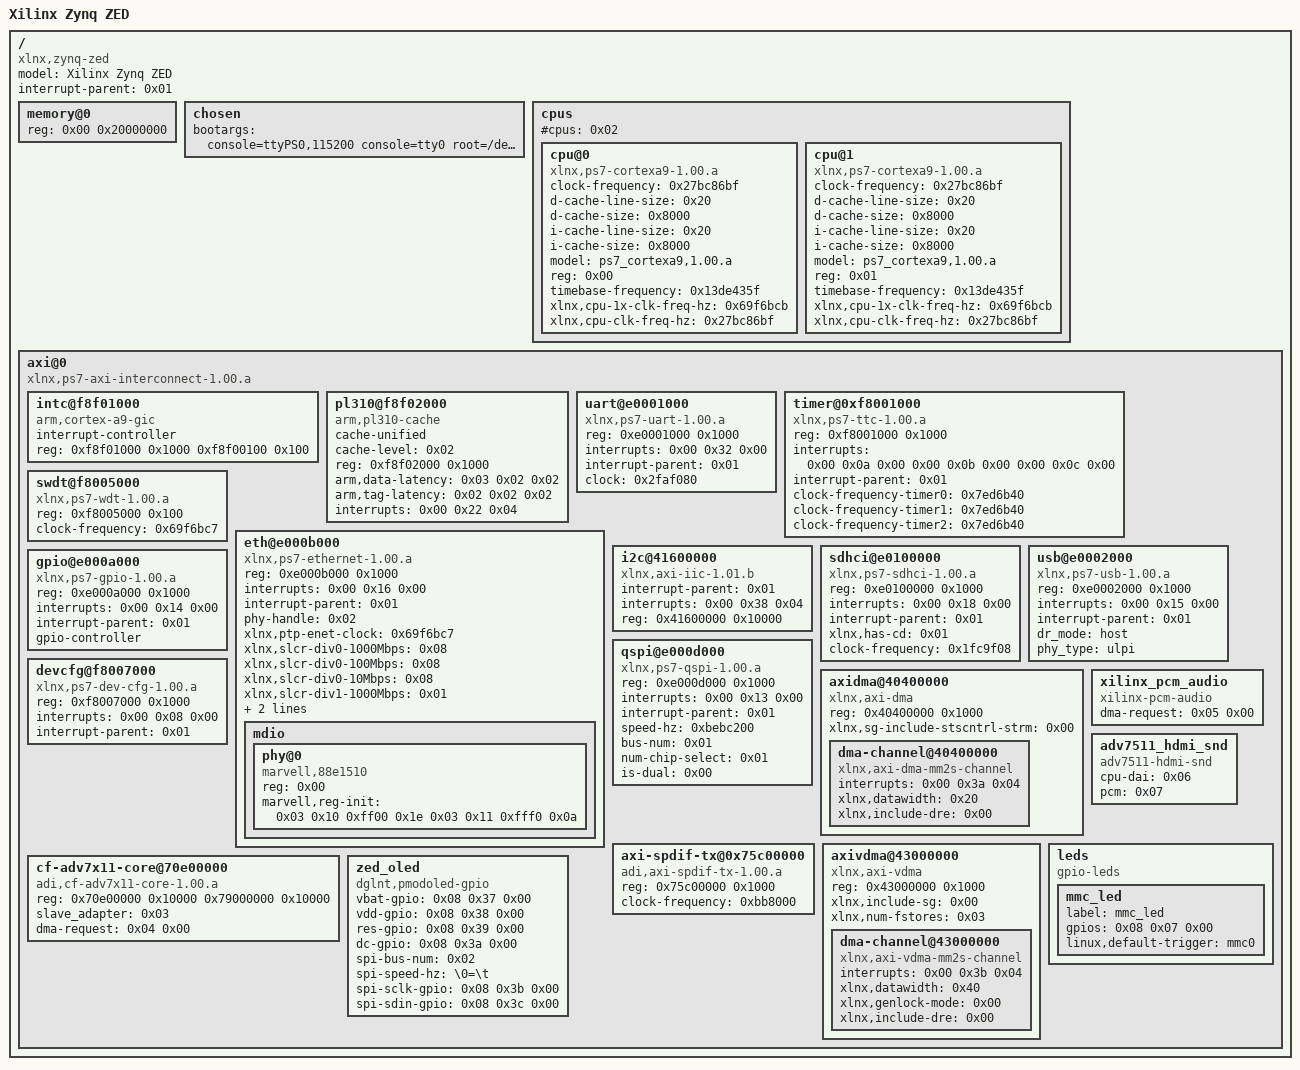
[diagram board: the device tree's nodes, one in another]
/dts-v1/;

/ {
	model = "Xilinx Zynq ZED";
	compatible = "xlnx,zynq-zed";
	#address-cells = <0x01>;
	#size-cells = <0x01>;
	interrupt-parent = <0x01>;

	memory@0 {
		device_type = "memory";
		reg = <0x00 0x20000000>;
	};

	chosen {
		bootargs = "console=ttyPS0,115200 console=tty0 root=/dev/ram rw initrd=0x800000,8M earlyprintk rootfstype=ext4 rootwait devtmpfs.mount=0";
		// linux,stdout-path = "/axi@0/uart@E0001000";
	};

	cpus {
		#address-cells = <0x01>;
		#cpus = <0x02>;
		#size-cells = <0x00>;

		cpu@0 {
			clock-frequency = <0x27bc86bf>;
			compatible = "xlnx,ps7-cortexa9-1.00.a";
			d-cache-line-size = <0x20>;
			d-cache-size = <0x8000>;
			device_type = "cpu";
			i-cache-line-size = <0x20>;
			i-cache-size = <0x8000>;
			model = "ps7_cortexa9,1.00.a";
			reg = <0x00>;
			timebase-frequency = <0x13de435f>;
			xlnx,cpu-1x-clk-freq-hz = <0x69f6bcb>;
			xlnx,cpu-clk-freq-hz = <0x27bc86bf>;
		};

		cpu@1 {
			clock-frequency = <0x27bc86bf>;
			compatible = "xlnx,ps7-cortexa9-1.00.a";
			d-cache-line-size = <0x20>;
			d-cache-size = <0x8000>;
			device_type = "cpu";
			i-cache-line-size = <0x20>;
			i-cache-size = <0x8000>;
			model = "ps7_cortexa9,1.00.a";
			reg = <0x01>;
			timebase-frequency = <0x13de435f>;
			xlnx,cpu-1x-clk-freq-hz = <0x69f6bcb>;
			xlnx,cpu-clk-freq-hz = <0x27bc86bf>;
		};
	};

	axi@0 {
		#address-cells = <0x01>;
		#size-cells = <0x01>;
		compatible = "xlnx,ps7-axi-interconnect-1.00.a\0simple-bus";
		ranges;

		intc@f8f01000 {
			interrupt-controller;
			compatible = "arm,cortex-a9-gic";
			#interrupt-cells = <0x03>;
			reg = <0xf8f01000 0x1000 0xf8f00100 0x100>;
			linux,phandle = <0x01>;
			phandle = <0x01>;
		};

		pl310@f8f02000 {
			compatible = "arm,pl310-cache";
			cache-unified;
			cache-level = <0x02>;
			reg = <0xf8f02000 0x1000>;
			arm,data-latency = <0x03 0x02 0x02>;
			arm,tag-latency = <0x02 0x02 0x02>;
			interrupts = <0x00 0x22 0x04>;
		};

		uart@e0001000 {
			compatible = "xlnx,ps7-uart-1.00.a";
			reg = <0xe0001000 0x1000>;
			interrupts = <0x00 0x32 0x00>;
			interrupt-parent = <0x01>;
			clock = <0x2faf080>;
		};

		timer@0xf8001000 {
			compatible = "xlnx,ps7-ttc-1.00.a";
			reg = <0xf8001000 0x1000>;
			interrupts = <0x00 0x0a 0x00 0x00 0x0b 0x00 0x00 0x0c 0x00>;
			interrupt-parent = <0x01>;
			clock-frequency-timer0 = <0x7ed6b40>;
			clock-frequency-timer1 = <0x7ed6b40>;
			clock-frequency-timer2 = <0x7ed6b40>;
		};

		swdt@f8005000 {
			device_type = "watchdog";
			compatible = "xlnx,ps7-wdt-1.00.a";
			reg = <0xf8005000 0x100>;
			clock-frequency = <0x69f6bc7>;
		};

		eth@e000b000 {
			compatible = "xlnx,ps7-ethernet-1.00.a";
			reg = <0xe000b000 0x1000>;
			interrupts = <0x00 0x16 0x00>;
			interrupt-parent = <0x01>;
			phy-handle = <0x02>;
			#address-cells = <0x01>;
			#size-cells = <0x00>;
			xlnx,ptp-enet-clock = <0x69f6bc7>;
			xlnx,slcr-div0-1000Mbps = <0x08>;
			xlnx,slcr-div0-100Mbps = <0x08>;
			xlnx,slcr-div0-10Mbps = <0x08>;
			xlnx,slcr-div1-1000Mbps = <0x01>;
			xlnx,slcr-div1-100Mbps = <0x05>;
			xlnx,slcr-div1-10Mbps = <0x32>;

			mdio {
				#address-cells = <0x01>;
				#size-cells = <0x00>;

				phy@0 {
					compatible = "marvell,88e1510";
					device_type = "ethernet-phy";
					reg = <0x00>;
					marvell,reg-init = <0x03 0x10 0xff00 0x1e 0x03 0x11 0xfff0 0x0a>;
					linux,phandle = <0x02>;
					phandle = <0x02>;
				};
			};
		};

		i2c@41600000 {
			compatible = "xlnx,axi-iic-1.01.b\0xlnx,xps-iic-2.00.a";
			interrupt-parent = <0x01>;
			interrupts = <0x00 0x38 0x04>;
			reg = <0x41600000 0x10000>;
			#size-cells = <0x00>;
			#address-cells = <0x01>;
			linux,phandle = <0x03>;
			phandle = <0x03>;
		};

		sdhci@e0100000 {
			compatible = "xlnx,ps7-sdhci-1.00.a";
			reg = <0xe0100000 0x1000>;
			interrupts = <0x00 0x18 0x00>;
			interrupt-parent = <0x01>;
			xlnx,has-cd = <0x01>;
			clock-frequency = <0x1fc9f08>;
		};

		usb@e0002000 {
			compatible = "xlnx,ps7-usb-1.00.a";
			reg = <0xe0002000 0x1000>;
			interrupts = <0x00 0x15 0x00>;
			interrupt-parent = <0x01>;
			dr_mode = "host";
			phy_type = "ulpi";
		};

		gpio@e000a000 {
			compatible = "xlnx,ps7-gpio-1.00.a";
			#gpio-cells = <0x02>;
			reg = <0xe000a000 0x1000>;
			interrupts = <0x00 0x14 0x00>;
			interrupt-parent = <0x01>;
			gpio-controller;
			linux,phandle = <0x08>;
			phandle = <0x08>;
		};

		qspi@e000d000 {
			compatible = "xlnx,ps7-qspi-1.00.a";
			reg = <0xe000d000 0x1000>;
			interrupts = <0x00 0x13 0x00>;
			interrupt-parent = <0x01>;
			speed-hz = <0xbebc200>;
			bus-num = <0x01>;
			num-chip-select = <0x01>;
			is-dual = <0x00>;
		};

		devcfg@f8007000 {
			compatible = "xlnx,ps7-dev-cfg-1.00.a";
			reg = <0xf8007000 0x1000>;
			interrupts = <0x00 0x08 0x00>;
			interrupt-parent = <0x01>;
		};

		axidma@40400000 {
			#address-cells = <0x01>;
			#size-cells = <0x01>;
			#dma-cells = <0x01>;
			compatible = "xlnx,axi-dma";
			reg = <0x40400000 0x1000>;
			xlnx,sg-include-stscntrl-strm = <0x00>;
			linux,phandle = <0x05>;
			phandle = <0x05>;

			dma-channel@40400000 {
				compatible = "xlnx,axi-dma-mm2s-channel";
				interrupts = <0x00 0x3a 0x04>;
				xlnx,datawidth = <0x20>;
				xlnx,include-dre = <0x00>;
			};
		};

		axi-spdif-tx@0x75c00000 {
			compatible = "adi,axi-spdif-tx-1.00.a";
			reg = <0x75c00000 0x1000>;
			clock-frequency = <0xbb8000>;
			linux,phandle = <0x06>;
			phandle = <0x06>;
		};

		axivdma@43000000 {
			#address-cells = <0x01>;
			#size-cells = <0x01>;
			#dma-cells = <0x01>;
			compatible = "xlnx,axi-vdma";
			reg = <0x43000000 0x1000>;
			xlnx,include-sg = <0x00>;
			xlnx,num-fstores = <0x03>;
			linux,phandle = <0x04>;
			phandle = <0x04>;

			dma-channel@43000000 {
				compatible = "xlnx,axi-vdma-mm2s-channel";
				interrupts = <0x00 0x3b 0x04>;
				xlnx,datawidth = <0x40>;
				xlnx,genlock-mode = <0x00>;
				xlnx,include-dre = <0x00>;
			};
		};

		cf-adv7x11-core@70e00000 {
			compatible = "adi,cf-adv7x11-core-1.00.a";
			reg = <0x70e00000 0x10000 0x79000000 0x10000>;
			slave_adapter = <0x03>;
			dma-request = <0x04 0x00>;
		};

		xilinx_pcm_audio {
			compatible = "xilinx-pcm-audio";
			dma-request = <0x05 0x00>;
			linux,phandle = <0x07>;
			phandle = <0x07>;
		};

		adv7511_hdmi_snd {
			compatible = "adv7511-hdmi-snd";
			cpu-dai = <0x06>;
			pcm = <0x07>;
		};

		leds {
			compatible = "gpio-leds";

			mmc_led {
				label = "mmc_led";
				gpios = <0x08 0x07 0x00>;
				linux,default-trigger = "mmc0";
			};
		};

		zed_oled {
			compatible = "dglnt,pmodoled-gpio";
			vbat-gpio = <0x08 0x37 0x00>;
			vdd-gpio = <0x08 0x38 0x00>;
			res-gpio = <0x08 0x39 0x00>;
			dc-gpio = <0x08 0x3a 0x00>;
			spi-bus-num = <0x02>;
			spi-speed-hz = "\0=\t";
			spi-sclk-gpio = <0x08 0x3b 0x00>;
			spi-sdin-gpio = <0x08 0x3c 0x00>;
		};
	};
};
